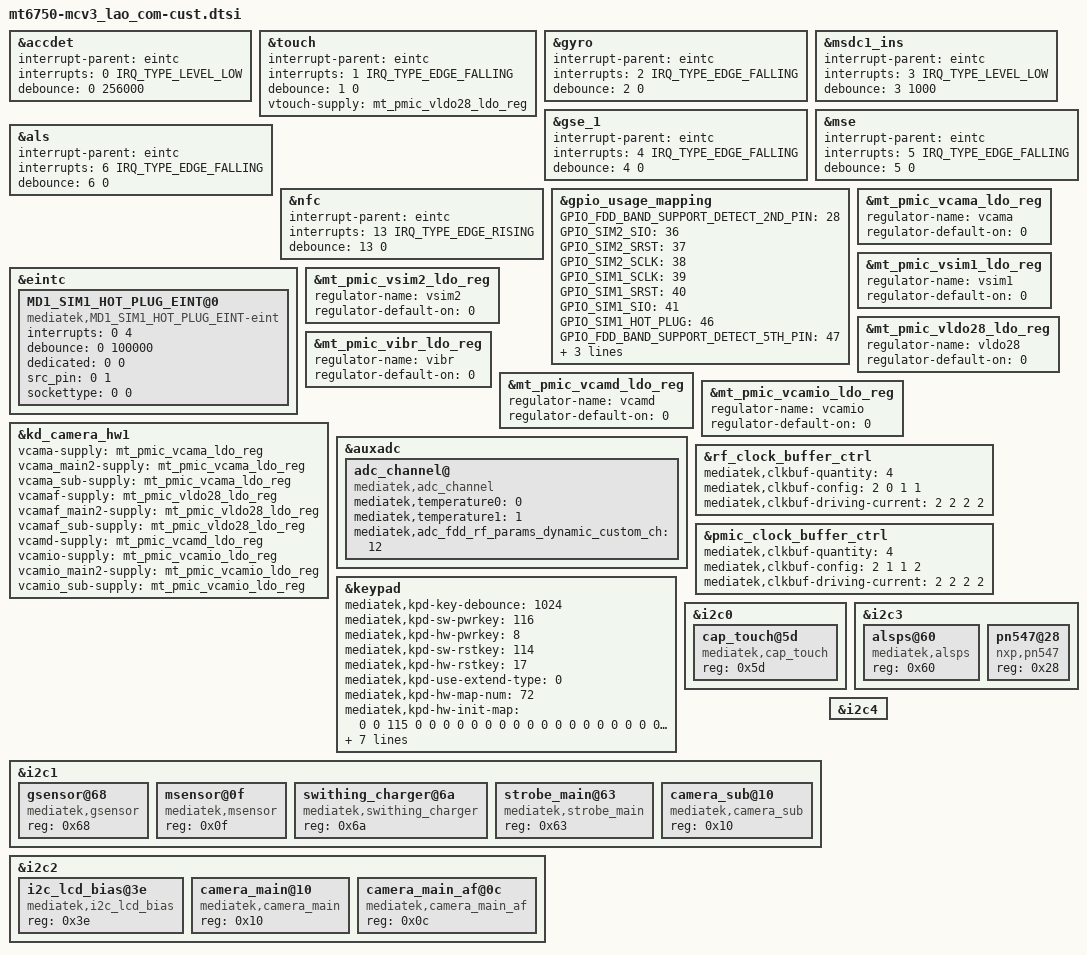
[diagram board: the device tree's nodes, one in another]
/*
 * Generated by MTK SP Drv_CodeGen Version 03.13.6  for MT6755. Copyright MediaTek Inc. (C) 2013.
 * Wed Sep 13 15:48:38 2017
 * Do Not Modify the File.
 */

#include <dt-bindings/interrupt-controller/irq.h>
#include <dt-bindings/interrupt-controller/arm-gic.h>

/*************************
 * EINT DTSI File
*************************/

&accdet {
	interrupt-parent = <&eintc>;
	interrupts = <0 IRQ_TYPE_LEVEL_LOW>;
	debounce = <0 256000>;
	status = "okay";
};
&touch {
	interrupt-parent = <&eintc>;
	interrupts = <1 IRQ_TYPE_EDGE_FALLING>;
	debounce = <1 0>;
	status = "okay";
};
&gyro {
	interrupt-parent = <&eintc>;
	interrupts = <2 IRQ_TYPE_EDGE_FALLING>;
	debounce = <2 0>;
	status = "okay";
};
&msdc1_ins {
	interrupt-parent = <&eintc>;
	interrupts = <3 IRQ_TYPE_LEVEL_LOW>;
	debounce = <3 1000>;
	status = "okay";
};
&gse_1 {
	interrupt-parent = <&eintc>;
	interrupts = <4 IRQ_TYPE_EDGE_FALLING>;
	debounce = <4 0>;
	status = "okay";
};
&mse {
	interrupt-parent = <&eintc>;
	interrupts = <5 IRQ_TYPE_EDGE_FALLING>;
	debounce = <5 0>;
	status = "okay";
};
&als {
	interrupt-parent = <&eintc>;
	interrupts = <6 IRQ_TYPE_EDGE_FALLING>;
	debounce = <6 0>;
	status = "okay";
};
&nfc {
	interrupt-parent = <&eintc>;
	interrupts = <13 IRQ_TYPE_EDGE_RISING>;
	debounce = <13 0>;
	status = "okay";
};


/********************
 * GPIO USAGE MAPPING DTSI File
****************/

&gpio_usage_mapping {
	GPIO_FDD_BAND_SUPPORT_DETECT_2ND_PIN = <28>;
	GPIO_SIM2_SIO = <36>;
	GPIO_SIM2_SRST = <37>;
	GPIO_SIM2_SCLK = <38>;
	GPIO_SIM1_SCLK = <39>;
	GPIO_SIM1_SRST = <40>;
	GPIO_SIM1_SIO = <41>;
	GPIO_SIM1_HOT_PLUG = <46>;
	GPIO_FDD_BAND_SUPPORT_DETECT_5TH_PIN = <47>;
	GPIO_FDD_BAND_SUPPORT_DETECT_4TH_PIN = <48>;
	GPIO_FDD_BAND_SUPPORT_DETECT_1ST_PIN = <55>;
	GPIO_FDD_BAND_SUPPORT_DETECT_3RD_PIN = <62>;
};


&eintc {
	MD1_SIM1_HOT_PLUG_EINT@0 {
		compatible = "mediatek,MD1_SIM1_HOT_PLUG_EINT-eint";
		interrupts = <0 4>;
		debounce = <0 100000>;
		dedicated = <0 0>;
		src_pin = <0 1>;
		sockettype=<0 0>;
		status = "okay";
	};
};


/*************************
 * PMIC DTSI File
*************************/

&mt_pmic_vcama_ldo_reg {
	regulator-name = "vcama";
	regulator-default-on = <0>; /* 0:skip, 1: off, 2:on */
	status = "okay";
};
&mt_pmic_vsim1_ldo_reg {
	regulator-name = "vsim1";
	regulator-default-on = <0>; /* 0:skip, 1: off, 2:on */
	status = "okay";
};
&mt_pmic_vsim2_ldo_reg {
	regulator-name = "vsim2";
	regulator-default-on = <0>; /* 0:skip, 1: off, 2:on */
	status = "okay";
};
&mt_pmic_vldo28_ldo_reg {
	regulator-name = "vldo28";
	regulator-default-on = <0>; /* 0:skip, 1: off, 2:on */
	status = "okay";
};
&mt_pmic_vibr_ldo_reg {
	regulator-name = "vibr";
	regulator-default-on = <0>; /* 0:skip, 1: off, 2:on */
	status = "okay";
};
&mt_pmic_vcamd_ldo_reg {
	regulator-name = "vcamd";
	regulator-default-on = <0>; /* 0:skip, 1: off, 2:on */
	status = "okay";
};
&mt_pmic_vcamio_ldo_reg {
	regulator-name = "vcamio";
	regulator-default-on = <0>; /* 0:skip, 1: off, 2:on */
	status = "okay";
};

&kd_camera_hw1 {
	vcama-supply = <&mt_pmic_vcama_ldo_reg>;
	vcama_main2-supply = <&mt_pmic_vcama_ldo_reg>;
	vcama_sub-supply = <&mt_pmic_vcama_ldo_reg>;

	vcamaf-supply = <&mt_pmic_vldo28_ldo_reg>;
	vcamaf_main2-supply = <&mt_pmic_vldo28_ldo_reg>;
	vcamaf_sub-supply = <&mt_pmic_vldo28_ldo_reg>;

	vcamd-supply = <&mt_pmic_vcamd_ldo_reg>;

	vcamio-supply = <&mt_pmic_vcamio_ldo_reg>;
	vcamio_main2-supply = <&mt_pmic_vcamio_ldo_reg>;
	vcamio_sub-supply = <&mt_pmic_vcamio_ldo_reg>;

	status = "okay";
};

&touch {
	vtouch-supply = <&mt_pmic_vldo28_ldo_reg>;
	status = "okay";
};


/********************************************
 *ADC DTSI File
********************************************/

&auxadc {
	adc_channel@ {
		compatible = "mediatek,adc_channel";
		mediatek,temperature0 = <0>;
		mediatek,temperature1 = <1>;
		mediatek,adc_fdd_rf_params_dynamic_custom_ch = <12>;
		status = "okay";
	};
};


/**********************************************
 *CLK_BUF DTSI File
********************************************/

&rf_clock_buffer_ctrl {
	mediatek,clkbuf-quantity = <4>;
	mediatek,clkbuf-config = <2 0 1 1>;
	mediatek,clkbuf-driving-current = <2 2 2 2>;
	status = "okay";
};

&pmic_clock_buffer_ctrl {
	mediatek,clkbuf-quantity = <4>;
	mediatek,clkbuf-config = <2 1 1 2>;
	mediatek,clkbuf-driving-current = <2 2 2 2>;
	status = "okay";
};


/**********************************************
 *Keypad DTSI File
********************************************/

&keypad{
	mediatek,kpd-key-debounce = <1024>;
	mediatek,kpd-sw-pwrkey = <116>;
	mediatek,kpd-hw-pwrkey = <8>;
	mediatek,kpd-sw-rstkey  = <114>;
	mediatek,kpd-hw-rstkey = <17>;
	mediatek,kpd-use-extend-type = <0>;
	/*HW Keycode [0~71] -> Linux Keycode*/
	mediatek,kpd-hw-map-num = <72>;
	mediatek,kpd-hw-init-map = <0 0 115 0 0 0 0 0 0 0 0 0 0 0 0 0 0 0 0 0 0 0 0 0 
				0 0 0 0 0 0 0 0 0 0 0 0 0 0 0 0 0 0 0 0 0 0 0 0 
				0 0 0 0 0 0 0 0 0 0 0 0 0 0 0 0 0 0 0 0 0 0 0 0 >;
	mediatek,kpd-pwrkey-eint-gpio = <0>;
	mediatek,kpd-pwkey-gpio-din  = <0>;
	mediatek,kpd-hw-dl-key0 = <2>;
	mediatek,kpd-hw-dl-key1 = <17>;
	mediatek,kpd-hw-dl-key2 = <8>;
	mediatek,kpd-hw-recovery-key = <2>;
	mediatek,kpd-hw-factory-key = <17>;
	status = "okay";
};


/*************************
 * I2C DTSI File
*************************/

&i2c0 {
	#address-cells = <1>;
	#size-cells = <0>;
	cap_touch@5d {
		compatible = "mediatek,cap_touch";
		reg = <0x5d>;
		status = "okay";
	};
};

&i2c1 {
	#address-cells = <1>;
	#size-cells = <0>;
	gsensor@68 {
		compatible = "mediatek,gsensor";
		reg = <0x68>;
		status = "okay";
	};
	msensor@0f {
		compatible = "mediatek,msensor";
		reg = <0x0f>;
		status = "okay";
	};
	swithing_charger@6a {
		compatible = "mediatek,swithing_charger";
		reg = <0x6a>;
		status = "okay";
	};
	strobe_main@63 {
		compatible = "mediatek,strobe_main";
		reg = <0x63>;
		status = "okay";
	};
	camera_sub@10 {
		compatible = "mediatek,camera_sub";
		reg = <0x10>;
		status = "okay";
	};
};

&i2c2 {
	#address-cells = <1>;
	#size-cells = <0>;
	i2c_lcd_bias@3e {
		compatible = "mediatek,i2c_lcd_bias";
		reg = <0x3e>;
		status = "okay";
	};
	camera_main@10 {
		compatible = "mediatek,camera_main";
		reg = <0x10>;
		status = "okay";
	};
	camera_main_af@0c {
		compatible = "mediatek,camera_main_af";
		reg = <0x0c>;
		status = "okay";
	};
};

&i2c3 {
	#address-cells = <1>;
	#size-cells = <0>;
	alsps@60 {
		compatible = "mediatek,alsps";
		reg = <0x60>;
		status = "okay";
	};
	pn547@28 {
		compatible = "nxp,pn547";
		reg = <0x28>;
		status = "okay";
	};
};

&i2c4 {
	#address-cells = <1>;
	#size-cells = <0>;
};



